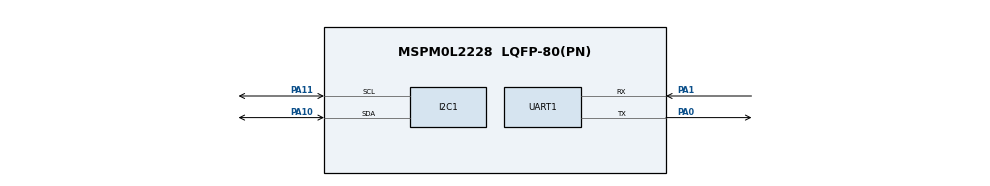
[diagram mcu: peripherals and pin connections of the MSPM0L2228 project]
//@cliArgs --device "MSPM0L222X" --package "LQFP-80(PN)" --part "Default"
//@v2CliArgs --device "MSPM0L2228" --package "LQFP-80(PN)"
// @cliArgs --board /ti/boards/LP_MSPM0L2228 --rtos nortos

/**
 * Import the modules used in this configuration.
 */
const I2C           = scripting.addModule("/ti/driverlib/I2C", {}, false);
const I2C1          = I2C.addInstance();
const SYSCTL        = scripting.addModule("/ti/driverlib/SYSCTL");
const UART          = scripting.addModule("/ti/driverlib/UART", {}, false);
const UART1         = UART.addInstance();
const ProjectConfig = scripting.addModule("/ti/project_config/ProjectConfig");

/**
 * Write custom configuration values to the imported modules.
 */
const mux8 = system.clockTree["LFXTMUX"];
scripting.suppress("Note: VBAT needs to be powered for LFCLK operation\\.", mux8, "inputSelect");

I2C1.basicEnableController             = true;
I2C1.basicTargetSecAddressEnable       = true;
I2C1.enableDMAEvent1                   = false;
I2C1.enableDMAEvent2                   = false;
I2C1.advAnalogGlitchFilter             = "DISABLED";
I2C1.advControllerTXFIFOTRIG           = "BYTES_1";
I2C1.intController                     = ["NACK","RXFIFO_TRIGGER","RX_DONE","TX_DONE"];
I2C1.$name                             = "I2C_BRIDGE";
I2C1.peripheral.$assign                = "I2C0";
I2C1.peripheral.sdaPin.$assign         = "PA10";
I2C1.peripheral.sclPin.$assign         = "PA11";

const Board              = scripting.addModule("/ti/driverlib/Board", {}, false);
Board.peripheral.$assign = "DEBUGSS";

SYSCTL.clockTreeEn           = true;
SYSCTL.forceDefaultClkConfig = true;

UART1.rxFifoThreshold                  = "DL_UART_RX_FIFO_LEVEL_ONE_ENTRY";
UART1.enableDMARX                      = false;
UART1.enableDMATX                      = false;
UART1.enabledInterrupts                = ["RX"];
UART1.$name                            = "UART_BRIDGE";
UART1.peripheral.$assign               = "UART0";
UART1.peripheral.rxPin.$assign         = "PA1";
UART1.peripheral.txPin.$assign         = "PA0";

ProjectConfig.switchCondition = true;
scripting.suppress("Migrating requires going through the Switch Board or Device menu in the Device View section\\.", ProjectConfig, "deviceSpin");
